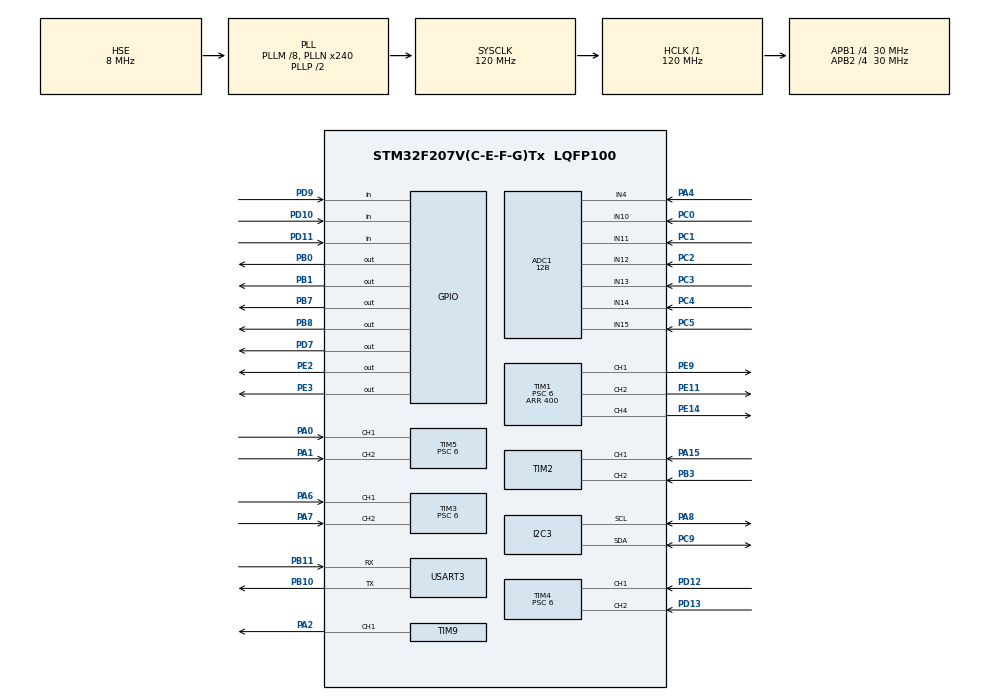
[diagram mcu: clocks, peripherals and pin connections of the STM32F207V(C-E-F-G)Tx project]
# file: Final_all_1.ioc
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ADC1.Channel-11\#ChannelRegularConversion=ADC_CHANNEL_4
ADC1.Channel-12\#ChannelRegularConversion=ADC_CHANNEL_10
ADC1.Channel-13\#ChannelRegularConversion=ADC_CHANNEL_11
ADC1.Channel-14\#ChannelRegularConversion=ADC_CHANNEL_12
ADC1.Channel-15\#ChannelRegularConversion=ADC_CHANNEL_13
ADC1.Channel-16\#ChannelRegularConversion=ADC_CHANNEL_14
ADC1.Channel-17\#ChannelRegularConversion=ADC_CHANNEL_15
ADC1.ClockPrescaler=ADC_CLOCK_SYNC_PCLK_DIV2
ADC1.ContinuousConvMode=ENABLE
ADC1.DMAContinuousRequests=ENABLE
ADC1.DataAlign=ADC_DATAALIGN_RIGHT
ADC1.DiscontinuousConvMode=DISABLE
ADC1.EOCSelection=ADC_EOC_SINGLE_CONV
ADC1.EnableAnalogWatchDog=false
ADC1.ExternalTrigConvEdge=ADC_EXTERNALTRIGCONVEDGE_NONE
ADC1.InjNumberOfConversion=0
ADC1.NbrOfConversion=7
ADC1.NbrOfConversionFlag=1
ADC1.Rank-11\#ChannelRegularConversion=1
ADC1.Rank-12\#ChannelRegularConversion=2
ADC1.Rank-13\#ChannelRegularConversion=3
ADC1.Rank-14\#ChannelRegularConversion=4
ADC1.Rank-15\#ChannelRegularConversion=5
ADC1.Rank-16\#ChannelRegularConversion=6
ADC1.Rank-17\#ChannelRegularConversion=7
ADC1.Resolution=ADC_RESOLUTION_12B
ADC1.SamplingTime-11\#ChannelRegularConversion=ADC_SAMPLETIME_3CYCLES
ADC1.SamplingTime-12\#ChannelRegularConversion=ADC_SAMPLETIME_3CYCLES
ADC1.SamplingTime-13\#ChannelRegularConversion=ADC_SAMPLETIME_3CYCLES
ADC1.SamplingTime-14\#ChannelRegularConversion=ADC_SAMPLETIME_3CYCLES
ADC1.SamplingTime-15\#ChannelRegularConversion=ADC_SAMPLETIME_3CYCLES
ADC1.SamplingTime-16\#ChannelRegularConversion=ADC_SAMPLETIME_3CYCLES
ADC1.SamplingTime-17\#ChannelRegularConversion=ADC_SAMPLETIME_3CYCLES
ADC1.ScanConvMode=ENABLE
ADC1.master=1
Dma.ADC1.0.Channel=DMA_CHANNEL_0
Dma.ADC1.0.Direction=DMA_PERIPH_TO_MEMORY
Dma.ADC1.0.FIFOMode=DMA_FIFOMODE_ENABLE
Dma.ADC1.0.FIFOThreshold=DMA_FIFO_THRESHOLD_FULL
Dma.ADC1.0.Instance=DMA2_Stream0
Dma.ADC1.0.MemBurst=DMA_MBURST_SINGLE
Dma.ADC1.0.MemDataAlignment=DMA_MDATAALIGN_WORD
Dma.ADC1.0.MemInc=DMA_MINC_ENABLE
Dma.ADC1.0.Mode=DMA_CIRCULAR
Dma.ADC1.0.PeriphBurst=DMA_PBURST_SINGLE
Dma.ADC1.0.PeriphDataAlignment=DMA_PDATAALIGN_WORD
Dma.ADC1.0.PeriphInc=DMA_PINC_DISABLE
Dma.ADC1.0.Priority=DMA_PRIORITY_LOW
Dma.Request0=ADC1
Dma.Request1=USART3_RX
Dma.Request2=USART3_TX
Dma.USART3_RX.1.Channel=DMA_CHANNEL_4
Dma.USART3_RX.1.Direction=DMA_PERIPH_TO_MEMORY
Dma.USART3_RX.1.FIFOMode=DMA_FIFOMODE_ENABLE
Dma.USART3_RX.1.FIFOThreshold=DMA_FIFO_THRESHOLD_FULL
Dma.USART3_RX.1.Instance=DMA1_Stream1
Dma.USART3_RX.1.MemBurst=DMA_MBURST_SINGLE
Dma.USART3_RX.1.MemDataAlignment=DMA_MDATAALIGN_BYTE
Dma.USART3_RX.1.MemInc=DMA_MINC_DISABLE
Dma.USART3_RX.1.Mode=DMA_CIRCULAR
Dma.USART3_RX.1.PeriphBurst=DMA_PBURST_SINGLE
Dma.USART3_RX.1.PeriphDataAlignment=DMA_PDATAALIGN_BYTE
Dma.USART3_RX.1.PeriphInc=DMA_PINC_DISABLE
Dma.USART3_RX.1.Priority=DMA_PRIORITY_LOW
Dma.USART3_TX.2.Channel=DMA_CHANNEL_4
Dma.USART3_TX.2.Direction=DMA_MEMORY_TO_PERIPH
Dma.USART3_TX.2.FIFOMode=DMA_FIFOMODE_ENABLE
Dma.USART3_TX.2.FIFOThreshold=DMA_FIFO_THRESHOLD_FULL
Dma.USART3_TX.2.Instance=DMA1_Stream3
Dma.USART3_TX.2.MemBurst=DMA_MBURST_SINGLE
Dma.USART3_TX.2.MemDataAlignment=DMA_MDATAALIGN_BYTE
Dma.USART3_TX.2.MemInc=DMA_MINC_DISABLE
Dma.USART3_TX.2.Mode=DMA_CIRCULAR
Dma.USART3_TX.2.PeriphBurst=DMA_PBURST_SINGLE
Dma.USART3_TX.2.PeriphDataAlignment=DMA_PDATAALIGN_BYTE
Dma.USART3_TX.2.PeriphInc=DMA_PINC_DISABLE
Dma.USART3_TX.2.Priority=DMA_PRIORITY_LOW
FREERTOS.Tasks01=defaultTask,0,128,StartDefaultTask,Default
Mcu.Family=STM32F2
Mcu.Name=STM32F207V(C-E-F-G)Tx
Mcu.Package=LQFP100
NVIC.DMA1_Stream1_IRQn=true\:5\:0\:true\:false\:true
NVIC.DMA1_Stream3_IRQn=true\:5\:0\:false\:false\:true
NVIC.DMA2_Stream0_IRQn=true\:5\:0\:true\:false\:true
NVIC.PriorityGroup=NVIC_PRIORITYGROUP_4
PA0-WKUP.Signal=S_TIM5_CH1
PA1.Signal=S_TIM5_CH2
PA15.Signal=S_TIM2_CH1_ETR
PA2.Signal=S_TIM9_CH1
PA4.Signal=ADCx_IN4
PA6.Signal=S_TIM3_CH1
PA7.Signal=S_TIM3_CH2
PA8.Mode=I2C
PA8.Signal=I2C3_SCL
PB0.Signal=GPIO_Output
PB1.Signal=GPIO_Output
PB10.Mode=Asynchronous
PB10.Signal=USART3_TX
PB11.Mode=Asynchronous
PB11.Signal=USART3_RX
PB3.Signal=S_TIM2_CH2
PB7.Signal=GPIO_Output
PB8.Signal=GPIO_Output
PC0.Signal=ADCx_IN10
PC1.Signal=ADCx_IN11
PC2.Signal=ADCx_IN12
PC3.Signal=ADCx_IN13
PC4.Signal=ADCx_IN14
PC5.Signal=ADCx_IN15
PC9.Mode=I2C
PC9.Signal=I2C3_SDA
PD10.Signal=GPIO_Input
PD11.Signal=GPIO_Input
PD12.Signal=S_TIM4_CH1
PD13.Signal=S_TIM4_CH2
PD7.Signal=GPIO_Output
PD9.Signal=GPIO_Input
PE11.Signal=S_TIM1_CH2
PE14.Signal=S_TIM1_CH4
PE2.Signal=GPIO_Output
PE3.Signal=GPIO_Output
PE9.Signal=S_TIM1_CH1
PH0-OSC_IN.Mode=HSE-External-Oscillator
PH0-OSC_IN.Signal=RCC_OSC_IN
PH1-OSC_OUT.Mode=HSE-External-Oscillator
PH1-OSC_OUT.Signal=RCC_OSC_OUT
ProjectManager.HeapSize=0x200
ProjectManager.StackSize=0x400
ProjectManager.TargetToolchain=MDK-ARM V5
RCC.48MHZClocksFreq_Value=60000000
RCC.AHBFreq_Value=120000000
RCC.APB1CLKDivider=RCC_HCLK_DIV4
RCC.APB1Freq_Value=30000000
RCC.APB1TimFreq_Value=60000000
RCC.APB2CLKDivider=RCC_HCLK_DIV4
RCC.APB2Freq_Value=30000000
RCC.APB2TimFreq_Value=60000000
RCC.CortexFreq_Value=120000000
RCC.HCLKFreq_Value=120000000
RCC.HSE_VALUE=8000000
RCC.HSI_VALUE=16000000
RCC.LSE_VALUE=32768
RCC.PLLM=8
RCC.PLLN=240
RCC.PLLSourceVirtual=RCC_PLLSOURCE_HSE
RCC.SYSCLKFreq_VALUE=120000000
RCC.SYSCLKSource=RCC_SYSCLKSOURCE_PLLCLK
RCC.VCOOutputFreq_Value=240000000
SH.ADCx_IN10.0=ADC1_IN10,IN10
SH.ADCx_IN11.0=ADC1_IN11,IN11
SH.ADCx_IN12.0=ADC1_IN12,IN12
SH.ADCx_IN13.0=ADC1_IN13,IN13
SH.ADCx_IN14.0=ADC1_IN14,IN14
SH.ADCx_IN15.0=ADC1_IN15,IN15
SH.ADCx_IN4.0=ADC1_IN4,IN4
SH.S_TIM1_CH1.0=TIM1_CH1,PWM Generation1 CH1
SH.S_TIM1_CH2.0=TIM1_CH2,PWM Generation2 CH2
SH.S_TIM1_CH4.0=TIM1_CH4,PWM Generation4 CH4
SH.S_TIM2_CH1_ETR.0=TIM2_CH1,Encoder_Interface
SH.S_TIM2_CH2.0=TIM2_CH2,Encoder_Interface
SH.S_TIM3_CH1.0=TIM3_CH1,Encoder_Interface
SH.S_TIM3_CH2.0=TIM3_CH2,Encoder_Interface
SH.S_TIM4_CH1.0=TIM4_CH1,Encoder_Interface
SH.S_TIM4_CH2.0=TIM4_CH2,Encoder_Interface
SH.S_TIM5_CH1.0=TIM5_CH1,Encoder_Interface
SH.S_TIM5_CH2.0=TIM5_CH2,Encoder_Interface
SH.S_TIM9_CH1.0=TIM9_CH1,PWM Generation1 CH1
TIM1.Channel-PWM\ Generation2\ CH2=TIM_CHANNEL_2
TIM1.Channel-PWM\ Generation4\ CH4=TIM_CHANNEL_4
TIM1.Period=400
TIM1.Prescaler=6
TIM3.Period=400
TIM3.Prescaler=6
TIM4.Period=400
TIM4.Prescaler=6
TIM5.Period=400
TIM5.Prescaler=6
TIM9.Period=2001
TIM9.Prescaler=161
TIM9.Pulse-PWM\ Generation1\ CH1=100
VP_FREERTOS_VS_ENABLE.Mode=Enabled
VP_TIM1_VS_ClockSourceINT.Mode=Internal
VP_TIM9_VS_ClockSourceINT.Mode=Internal
board=Final_all_1

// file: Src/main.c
/**
  ******************************************************************************
  * File Name          : main.c
  * Description        : Main program body
  ******************************************************************************
  *
  * COPYRIGHT(c) 2016 STMicroelectronics
  *
  * Redistribution and use in source and binary forms, with or without modification,
  * are permitted provided that the following conditions are met:
  *   1. Redistributions of source code must retain the above copyright notice,
  *      this list of conditions and the following disclaimer.
  *   2. Redistributions in binary form must reproduce the above copyright notice,
  *      this list of conditions and the following disclaimer in the documentation
  *      and/or other materials provided with the distribution.
  *   3. Neither the name of STMicroelectronics nor the names of its contributors
  *      may be used to endorse or promote products derived from this software
  *      without specific prior written permission.
  *
  * THIS SOFTWARE IS PROVIDED BY THE COPYRIGHT HOLDERS AND CONTRIBUTORS "AS IS"
  * AND ANY EXPRESS OR IMPLIED WARRANTIES, INCLUDING, BUT NOT LIMITED TO, THE
  * IMPLIED WARRANTIES OF MERCHANTABILITY AND FITNESS FOR A PARTICULAR PURPOSE ARE
  * DISCLAIMED. IN NO EVENT SHALL THE COPYRIGHT HOLDER OR CONTRIBUTORS BE LIABLE
  * FOR ANY DIRECT, INDIRECT, INCIDENTAL, SPECIAL, EXEMPLARY, OR CONSEQUENTIAL
  * DAMAGES (INCLUDING, BUT NOT LIMITED TO, PROCUREMENT OF SUBSTITUTE GOODS OR
  * SERVICES; LOSS OF USE, DATA, OR PROFITS; OR BUSINESS INTERRUPTION) HOWEVER
  * CAUSED AND ON ANY THEORY OF LIABILITY, WHETHER IN CONTRACT, STRICT LIABILITY,
  * OR TORT (INCLUDING NEGLIGENCE OR OTHERWISE) ARISING IN ANY WAY OUT OF THE USE
  * OF THIS SOFTWARE, EVEN IF ADVISED OF THE POSSIBILITY OF SUCH DAMAGE.
  *
  ******************************************************************************
  */
#include "stm32f2xx_hal.h"
#include "cmsis_os.h"
#include "adc.h"
#include "dma.h"
#include "i2c.h"
#include "tim.h"
#include "usart.h"
#include "gpio.h"

/* average PWM frequency assumed to be 25 khz. For more information
check the the timer frequency and the prescaler of the motor pwm pins */
#define pwm_period 400

/* conditional compiling for including sensor encoding */
#define ENCODE

HAL_StatusTypeDef status2;                                      // return type of functions, mainly used for debugging

#define packet_size 7*sizeof(uint32_t)                         // size of the packet to be sent through UART(sensor data)
#define headers 5                                               // additional overhead of the packet

#define pulse_1 TIM1->CCR1       //n2                           // compare registers of channels for motor pwm
#define pulse_2 TIM1->CCR2       //n3
#define pulse_3 TIM1->CCR4       //n1

/* initialize led gpio pin */
#define Led_gpio      GPIOE
#define Led_pin       GPIO_PIN_2

/* encoder pins*/
#define sens_gpio     GPIOD
#define sens_ph1_pin  GPIO_PIN_11
#define sens_ph2_pin  GPIO_PIN_10
#define sens_ph3_pin  GPIO_PIN_9

/* Motor controller dedicated pins */
#define DcCal_gpio    GPIOD
#define DcCal_pin     GPIO_PIN_7
#define EnGate_gpio   GPIOB
#define EnGate_pin    GPIO_PIN_8

/* ADC PIN and Port Initialization */

#define pot_port      GPIOC
#define pot_1         GPIO_PIN_0      // 1
#define pot_2         GPIO_PIN_1
#define pot_3         GPIO_PIN_2
#define pot_4         GPIO_PIN_3
#define pot_5         GPIO_PIN_4
#define pot_6         GPIO_PIN_5        // 6

#define bat_term      GPIOA             // battery voltage
#define bat_term_pin  GPIO_PIN_4        // 0

/* pins for motor pwm */

#define Phase_gpioH    GPIOB
#define ph_u_h        GPIO_PIN_0

#define ph_v_h        GPIO_PIN_7

#define ph_w_h        GPIO_PIN_1

#define Phase_gpioL    GPIOE
#define ph_u_l        GPIO_PIN_14         //N1
#define ph_v_l        GPIO_PIN_11         //N3
#define ph_w_l        GPIO_PIN_9          //N2

#define servo_pin		GPIO_PIN_2
#define servo_d TIM9->CCR1

unsigned char packet[packet_size + headers];        // total size of packet
osThreadId hscheduler,himu,hmotor,hled;
osSemaphoreId sema_imu_id,sema_sched_id;
unsigned char state = 0;                  // rotor state of bldc
int cnt = 0;
uint8_t status_i2c = 0;

/* volatile buffers for data collection from sensors using or not using DMA */
 __IO uint32_t imu_data[6];

 __IO int8_t recev;

uint8_t accel_data[6];
uint8_t gyro_data[6];

uint32_t adc_values[7];

 __IO uint32_t sens51[8];
 __IO uint32_t sens52[8];
 __IO uint32_t sens31[8];
 __IO uint32_t sens32[8];
 __IO uint32_t sens41[8];
 __IO uint32_t sens42[8];
 __IO uint32_t sens21[8];
 __IO uint32_t sens22[8];

 uint8_t anv=0x30;

/* USER CODE BEGIN PV */
/* Private variables ---------------------------------------------------------*/

/* USER CODE END PV */

void SystemClock_Config(void);
void MX_FREERTOS_Init(void);
void motor_rotate_forward(char sens, uint8_t duty_motor);
void motor_rotate_backward(char sens, uint8_t duty_motor);
static void scheduler_thread(void const *argument);
void adc_init_values();
void imu_data_collect();
void packet_form(uint32_t *adc_d);
static void imu_thread(void const *argument);
static void led_thread(void const *argument);

/* USER CODE BEGIN PFP */
/* Private function prototypes -----------------------------------------------*/

/* USER CODE END PFP */

int main(void)
 {

  /* MCU Configuration----------------------------------------------------------*/

  /* Reset of all peripherals, Initializes the Flash interface and the Systick. */
  HAL_Init();

  /* Configure the system clock */
  SystemClock_Config();
	  uint8_t i2c_id = 0;
  uint8_t send_i2c = 0;
  /* Initialize all configured peripherals */
  MX_GPIO_Init();
  MX_DMA_Init();
  MX_ADC1_Init();
  MX_I2C3_Init();
  MX_TIM1_Init();
  MX_TIM2_Init();
  MX_TIM3_Init();
  MX_TIM4_Init();
  MX_TIM5_Init();
  MX_TIM9_Init();
  MX_USART3_UART_Init();

	adc_init_values();
	HAL_TIM_Base_Start(&htim1);

  /* PWM setup for Nchannel MOSFETS */
  HAL_TIM_PWM_Start(&htim1, TIM_CHANNEL_1);
  HAL_TIM_PWM_Start(&htim1, TIM_CHANNEL_2);
  HAL_TIM_PWM_Start(&htim1, TIM_CHANNEL_4);

  HAL_TIM_PWM_Start(&htim9, TIM_CHANNEL_1);
  /* USER CODE BEGIN 2 */
	/* Initialize enable pins of motor controller */
	HAL_GPIO_WritePin(DcCal_gpio,DcCal_pin,GPIO_PIN_RESET);
  HAL_GPIO_WritePin(EnGate_gpio,EnGate_pin,GPIO_PIN_SET);

	/* read the device ID*/
	status2=HAL_I2C_Mem_Read(&hi2c3,0xD1,0x75,1,&i2c_id,1,10);
  HAL_Delay(10);
	/* Accelerometer and Gyroscope Initialization for resolution and sensitivity, see datasheet */
  send_i2c=0x00;
  HAL_I2C_Mem_Write(&hi2c3,0xD0,0x6B,1,&send_i2c,1,10);
  send_i2c=0x10;
  HAL_I2C_Mem_Write(&hi2c3,0xD0,0x1C,1,&send_i2c,1,10);
  send_i2c=0x18;
  HAL_I2C_Mem_Write(&hi2c3,0xD0,0x18,1,&send_i2c,1,10);
  /* USER CODE END 2 */
	recev=-20;

	HAL_ADC_Start_DMA(&hadc1,adc_values,7*sizeof(adc_values[0]));
	 /* Transmit the packet continuously through DMA */
  //HAL_UART_Transmit_DMA(&huart3,(uint8_t *)packet, sizeof(packet));
  /* Receive the command, one byte of signed integer value */
  HAL_UART_Receive_DMA(&huart3,(int8_t *)&recev,1);
	//HAL_UART_Transmit_DMA(&huart3,&anv,sizeof(anv));
	//HAL_UART_Transmit_DMA(&huart3,(uint8_t *)&recev, sizeof(int8_t));
  /* Start ADC conversions and save the value to memory through DMA. 7 channels 7 memory positions*/
  //
  /* Switch on the LED for one second */
  /* Call init function for freertos objects (in freertos.c) */
  MX_FREERTOS_Init();

	osSemaphoreDef(sem1);
	sema_sched_id=osSemaphoreCreate(osSemaphore(sem1),1);

	osThreadDef(scheduler,scheduler_thread,osPriorityRealtime,0,configMINIMAL_STACK_SIZE);
	hscheduler=osThreadCreate(osThread(scheduler),NULL);

  /* Start scheduler */
  osKernelStart();
	//scheduler_thread(NULL);

  /* We should never get here as control is now taken by the scheduler */

  /* Infinite loop */
  while (1)
  {

  }

}

static void motor_thread(void const *argument)
{
	int a=0;
	while (1)
  {
    /* get the rotor state of the bldc */
    state = HAL_GPIO_ReadPin(sens_gpio,sens_ph1_pin);
    state = state << 1;
    state |= HAL_GPIO_ReadPin(sens_gpio,sens_ph2_pin);
    state = state << 1;
    state |= HAL_GPIO_ReadPin(sens_gpio,sens_ph3_pin);
    a++;
    /* IMU data collection and packet formation */
    /* There is no interrupt involved with UART hence its mostly polling
       if recev is positive then direction is forward, incase of negative,
        direction is reverse */
    if(recev >= 0)
    {

      motor_rotate_forward(state, abs(recev));
    }
    else
    {
      motor_rotate_backward(state, abs(recev));
    }

  }
}
static void scheduler_thread(void const *argument)
{
	while(1)
	{
	osSemaphoreWait(sema_sched_id,osWaitForever);
	osThreadDef(imu,imu_thread,osPriorityHigh,0,configMINIMAL_STACK_SIZE);
	osThreadDef(motor,motor_thread,osPriorityHigh,0,configMINIMAL_STACK_SIZE);
	osThreadDef(ledt,led_thread,osPriorityHigh,0,configMINIMAL_STACK_SIZE);
	//himu=osThreadCreate(osThread(imu),NULL);
	hmotor=osThreadCreate(osThread(motor),NULL);
	hled=osThreadCreate(osThread(ledt),NULL);

	}

}
static void led_thread(void const *argument)
{
		int dut=0;
		while(1)
		{
			HAL_GPIO_TogglePin(Led_gpio,Led_pin);
			anv++;
			if(anv%2==0)
			{
				servo_d=200;
			}
			else servo_d=101;
			osDelay(2000);
		}
}
static void imu_thread(void const *argument)
{
	while(1)
	{
		packet_form(adc_values);
		osDelay(1000);
	}
}

void GPIO_pwm(uint16_t GPIO_Pin, GPIO_PinState PinState, uint8_t duty)
{
  /* calculation of duty cycle relative to period */
  uint8_t duty_cycle_motor = 0;
  duty_cycle_motor = (duty * pwm_period)/127;
  /* if pin state is set apply the duty cycle value to the compare register of the particular pin */
  if(PinState == GPIO_PIN_SET)
  {
    switch(GPIO_Pin)
     {
        case(ph_u_l):
          pulse_3 = duty_cycle_motor;
        break;

        case(ph_v_l):
          pulse_2 = duty_cycle_motor;
        break;

        case(ph_w_l):
          pulse_1 = duty_cycle_motor;
        break;

        default:
        break;
    }
  }
  /* if pin state is reset then reset the pin */
  else
  {
    switch(GPIO_Pin)
     {
        case(ph_u_l):
         pulse_3 = 0;
        break;

        case(ph_v_l):
          pulse_2 = 0;
        break;

        case(ph_w_l):
          pulse_1 = 0;
        break;

        default:
        break;
      }
  }
}
/* This function returns NULL and is mostly responsible for driving the BLDC motor in forward direction
   The low side of the MOSFETs are responsible for providing PWMs while the high side of the MOSFETs are
    hard coded. The MOSFETs are arranged in a hex converter configuration. There are 6 rotor states.*/
void motor_rotate_forward(char sens, uint8_t duty_motor)
{
    switch(sens) {
      case 5:
        GPIO_pwm(ph_u_l,GPIO_PIN_RESET,duty_motor);
        HAL_GPIO_WritePin(Phase_gpioH,ph_v_h,GPIO_PIN_RESET);
        HAL_GPIO_WritePin(Phase_gpioH,ph_w_h,GPIO_PIN_RESET);
        GPIO_pwm(ph_w_l,GPIO_PIN_RESET,duty_motor);
        GPIO_pwm(ph_v_l,GPIO_PIN_SET, duty_motor);
        HAL_GPIO_WritePin(Phase_gpioH,ph_u_h,GPIO_PIN_SET);
        break;
      case 4:
        HAL_GPIO_WritePin(Phase_gpioH,ph_v_h,GPIO_PIN_RESET);
        GPIO_pwm(ph_u_l,GPIO_PIN_RESET,duty_motor);
        GPIO_pwm(ph_v_l,GPIO_PIN_RESET,duty_motor);
        HAL_GPIO_WritePin(Phase_gpioH,ph_w_h,GPIO_PIN_RESET);
        HAL_GPIO_WritePin(Phase_gpioH,ph_u_h,GPIO_PIN_SET);
        GPIO_pwm(ph_w_l,GPIO_PIN_SET,duty_motor);
        break;
      case 6:
        HAL_GPIO_WritePin(Phase_gpioH,ph_u_h,GPIO_PIN_RESET);
        GPIO_pwm(ph_u_l,GPIO_PIN_RESET,duty_motor);
        GPIO_pwm(ph_v_l,GPIO_PIN_RESET,duty_motor);
        HAL_GPIO_WritePin(Phase_gpioH,ph_w_h,GPIO_PIN_RESET);
        HAL_GPIO_WritePin(Phase_gpioH,ph_v_h,GPIO_PIN_SET);
        GPIO_pwm(ph_w_l,GPIO_PIN_SET,duty_motor);
        break;
      case 2:
        HAL_GPIO_WritePin(Phase_gpioH,ph_u_h,GPIO_PIN_RESET);
        GPIO_pwm(ph_v_l,GPIO_PIN_RESET,duty_motor);
        HAL_GPIO_WritePin(Phase_gpioH,ph_w_h,GPIO_PIN_RESET);
        GPIO_pwm(ph_w_l,GPIO_PIN_RESET,duty_motor);
        GPIO_pwm(ph_u_l,GPIO_PIN_SET,duty_motor);
        HAL_GPIO_WritePin(Phase_gpioH,ph_v_h,GPIO_PIN_SET);
        break;
      case 3:
        HAL_GPIO_WritePin(Phase_gpioH,ph_u_h,GPIO_PIN_RESET);
        HAL_GPIO_WritePin(Phase_gpioH,ph_v_h,GPIO_PIN_RESET);
        GPIO_pwm(ph_v_l,GPIO_PIN_RESET,duty_motor);
        GPIO_pwm(ph_w_l,GPIO_PIN_RESET,duty_motor);
        HAL_GPIO_WritePin(Phase_gpioH,ph_w_h,GPIO_PIN_SET);
        GPIO_pwm(ph_u_l,GPIO_PIN_SET,duty_motor);
        break;
      case 1:
        HAL_GPIO_WritePin(Phase_gpioH,ph_u_h,GPIO_PIN_RESET);
        GPIO_pwm(ph_u_l,GPIO_PIN_RESET,duty_motor);
        HAL_GPIO_WritePin(Phase_gpioH,ph_v_h,GPIO_PIN_RESET);
        GPIO_pwm(ph_w_l,GPIO_PIN_RESET,duty_motor);
        GPIO_pwm(ph_v_l,GPIO_PIN_SET,duty_motor);
        HAL_GPIO_WritePin(Phase_gpioH,ph_w_h,GPIO_PIN_SET);
        break;
      default:
        while(1);
      }
}

/* This function returns NULL and is mostly responsible for driving the BLDC motor in reverse direction
   The low side of the MOSFETs are responsible for providing PWMs while the high side of the MOSFETs are
    hard coded. The MOSFETs are arranged in a hex converter configuration. There are 6 rotor states.*/
void motor_rotate_backward(char sens, uint8_t duty_motor) {
  switch(sens) {
    case 4:
      HAL_GPIO_WritePin(Phase_gpioH,ph_w_h,GPIO_PIN_RESET);
      GPIO_pwm(ph_w_l,GPIO_PIN_RESET,duty_motor);
      GPIO_pwm(ph_v_l,GPIO_PIN_RESET,duty_motor);
      HAL_GPIO_WritePin(Phase_gpioH,ph_u_h,GPIO_PIN_RESET);
      GPIO_pwm(ph_u_l,GPIO_PIN_SET,duty_motor);
      HAL_GPIO_WritePin(Phase_gpioH,ph_v_h,GPIO_PIN_SET);

      break;
    case 6:
      HAL_GPIO_WritePin(Phase_gpioH,ph_v_h,GPIO_PIN_RESET);
      GPIO_pwm(ph_v_l,GPIO_PIN_RESET,duty_motor);
      HAL_GPIO_WritePin(Phase_gpioH,ph_u_h,GPIO_PIN_RESET);
      GPIO_pwm(ph_w_l,GPIO_PIN_RESET,duty_motor);
      HAL_GPIO_WritePin(Phase_gpioH,ph_w_h,GPIO_PIN_SET);
      GPIO_pwm(ph_u_l,GPIO_PIN_SET,duty_motor);
      break;
    case 2:
      HAL_GPIO_WritePin(Phase_gpioH,ph_u_h,GPIO_PIN_RESET);
      GPIO_pwm(ph_u_l,GPIO_PIN_RESET,duty_motor);
      HAL_GPIO_WritePin(Phase_gpioH,ph_v_h,GPIO_PIN_RESET);
      GPIO_pwm(ph_w_l,GPIO_PIN_RESET,duty_motor);
      GPIO_pwm(ph_v_l,GPIO_PIN_SET,duty_motor);
      HAL_GPIO_WritePin(Phase_gpioH,ph_w_h,GPIO_PIN_SET);
      break;
    case 3:
      HAL_GPIO_WritePin(Phase_gpioH,ph_w_h,GPIO_PIN_RESET);
      GPIO_pwm(ph_w_l,GPIO_PIN_RESET,duty_motor);
      GPIO_pwm(ph_u_l,GPIO_PIN_RESET,duty_motor);
      HAL_GPIO_WritePin(Phase_gpioH,ph_v_h,GPIO_PIN_RESET);
      HAL_GPIO_WritePin(Phase_gpioH,ph_u_h,GPIO_PIN_SET);
      GPIO_pwm(ph_v_l,GPIO_PIN_SET,duty_motor);

      break;
    case 1:
      HAL_GPIO_WritePin(Phase_gpioH,ph_v_h,GPIO_PIN_RESET);
      GPIO_pwm(ph_v_l,GPIO_PIN_RESET,duty_motor);
      HAL_GPIO_WritePin(Phase_gpioH,ph_w_h,GPIO_PIN_RESET);
      GPIO_pwm(ph_u_l,GPIO_PIN_RESET,duty_motor);
      GPIO_pwm(ph_w_l,GPIO_PIN_SET,duty_motor);
      HAL_GPIO_WritePin(Phase_gpioH,ph_u_h,GPIO_PIN_SET);
      break;
    case 5:
      HAL_GPIO_WritePin(Phase_gpioH,ph_u_h,GPIO_PIN_RESET);
      GPIO_pwm(ph_u_l,GPIO_PIN_RESET,duty_motor);
      GPIO_pwm(ph_v_l,GPIO_PIN_RESET,duty_motor);
      HAL_GPIO_WritePin(Phase_gpioH,ph_w_h,GPIO_PIN_RESET);
      HAL_GPIO_WritePin(Phase_gpioH,ph_v_h,GPIO_PIN_SET);
      GPIO_pwm(ph_w_l,GPIO_PIN_SET,duty_motor);
      break;
    default:
      while(1);
    }
}

void adc_init_values()
{
  uint8_t i = 0;
  for(i=0;i<7;i++)
  {
    adc_values[i] = 0x55555555;
  }
}

void packet_form(uint32_t *adc_d)
{
  uint8_t count_packet = 0;
  uint8_t packet_current = 2;
  uint32_t sum_protect = 0;
  uint8_t count_data = 0;
  packet[0] = 'A';
  packet[1] = 'A';
  for(count_packet = 0; count_packet < (7*sizeof(uint32_t)); count_packet+=4)
  {
    /* 32 bit data to be saved in 4 8 bit locations */
    packet[packet_current+count_packet] = (unsigned char)(*(adc_d+count_data)>>24);
    packet[packet_current+count_packet+1] = (unsigned char)(*(adc_d+count_data)>>16);
    packet[packet_current+count_packet+2] = (unsigned char)(*(adc_d+count_data)>>8);
    packet[packet_current+count_packet+3] = (unsigned char)(*(adc_d+count_data));
    count_data++;
  }
  count_data = 0;
  packet_current += count_packet;
  /*for(count_packet = 0; count_packet < 6*sizeof(uint32_t); count_packet+=2)
  {
    /* 16 bit data to be saved in 2 8 bit locations
    packet[packet_current+count_packet] = (unsigned char)(*(imu_d+count_data)>>8);
    packet[packet_current+count_packet+3] = (unsigned char)*(imu_d+count_data);
    count_data++;
  }
  packet_current += count_packet;*/
  packet[packet_current+1] = '5';
  packet[packet_current+2] = '5';
  /* checksum is sum of all data */
  for(count_packet = 2; count_packet < (packet_size + headers - 3); count_packet++)
  {
    sum_protect += packet[count_packet];
  }
  packet[packet_current] = (unsigned char)sum_protect;
}
void imu_data_collect()
{
    HAL_I2C_Mem_Read(&hi2c3,0xD1,0x3B,1,accel_data,6,1);
    HAL_I2C_Mem_Read(&hi2c3,0xD1,0x43,1,gyro_data,6,1);

    imu_data[0] = ((accel_data[0] << 8) | accel_data[1]);       // 16 bit IMU data read as 8 bit and saved as 16 bit
    imu_data[1] = ((accel_data[2] << 8) | accel_data[3]);
    imu_data[2] = ((accel_data[4] << 8) | accel_data[5]);
    imu_data[3] = ((gyro_data[0] << 8) | gyro_data[1]);
    imu_data[4] = ((gyro_data[2] << 8) | gyro_data[3]);
    imu_data[5] = ((gyro_data[4] << 8) | gyro_data[5]);
}
/** System Clock Configuration
*/
void SystemClock_Config(void)
{

  RCC_OscInitTypeDef RCC_OscInitStruct;
  RCC_ClkInitTypeDef RCC_ClkInitStruct;

  RCC_OscInitStruct.OscillatorType = RCC_OSCILLATORTYPE_HSE;
  RCC_OscInitStruct.HSEState = RCC_HSE_ON;
  RCC_OscInitStruct.PLL.PLLState = RCC_PLL_ON;
  RCC_OscInitStruct.PLL.PLLSource = RCC_PLLSOURCE_HSE;
  RCC_OscInitStruct.PLL.PLLM = 8;
  RCC_OscInitStruct.PLL.PLLN = 240;
  RCC_OscInitStruct.PLL.PLLP = RCC_PLLP_DIV2;
  RCC_OscInitStruct.PLL.PLLQ = 4;
  HAL_RCC_OscConfig(&RCC_OscInitStruct);

  RCC_ClkInitStruct.ClockType = RCC_CLOCKTYPE_HCLK|RCC_CLOCKTYPE_SYSCLK
                              |RCC_CLOCKTYPE_PCLK1|RCC_CLOCKTYPE_PCLK2;
  RCC_ClkInitStruct.SYSCLKSource = RCC_SYSCLKSOURCE_PLLCLK;
  RCC_ClkInitStruct.AHBCLKDivider = RCC_SYSCLK_DIV1;
  RCC_ClkInitStruct.APB1CLKDivider = RCC_HCLK_DIV4;
  RCC_ClkInitStruct.APB2CLKDivider = RCC_HCLK_DIV4;
  HAL_RCC_ClockConfig(&RCC_ClkInitStruct, FLASH_LATENCY_3);

  HAL_SYSTICK_Config(HAL_RCC_GetHCLKFreq()/1000);

  HAL_SYSTICK_CLKSourceConfig(SYSTICK_CLKSOURCE_HCLK);

  /* SysTick_IRQn interrupt configuration */
  HAL_NVIC_SetPriority(SysTick_IRQn, 15, 0);
}

/************************ (C) COPYRIGHT STMicroelectronics *****END OF FILE****/
